# STM32MP21_CA35 register map
File version: 0.4
CPU: CM33 r0p1, little endian, MPU, FPU, vendor SysTick, 8 interrupt priority bits
Registers are 32-bit, read-write, reset 0x0 unless marked. A register's access mark holds for its fields unless they carry their own. Offsets are from the block's base; [hi:lo] are bit positions; {n}, {i} and the like mark numbered series; 'fields as' and 'values as' point back to an identical list.

## MDF1 — MDF register block
Base 0x404D0000
Same registers: MDF1_S 0x504D0000
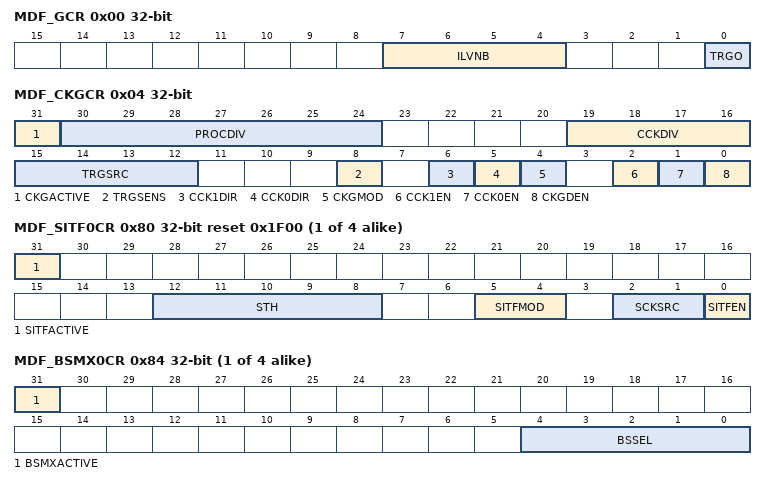
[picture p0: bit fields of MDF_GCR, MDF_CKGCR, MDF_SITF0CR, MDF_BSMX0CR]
0x00 MDF_GCR — MDF global control register
  [7:4] ILVNB — Interleaved number This bit field is set and reset by software. it enables or disables the interleaved-transfer mode and defines how many digital filters work in this mode. This bit field cannot be changed when DFLTEN = 1 in MDF_DFLT0CR. ... Note: This bit field can be write-protected (refer to Section 44.4.15 for details).
    0=Interleaved-transfer mode disabled; 1=Data from DFLT0 and DFLT1 are interleaved; 2=Data from DFLT0, DFLT1 and DFLT2 are interleaved; 15=Data from DFLT0 to DFLT15 are interleaved
  [0] TRGO — Trigger output control This bit is set by software and reset by hardware. It is used to start the acquisition of several filters synchronously. It is also able to synchronize several MDF together by controlling the mdf_trgo signal.
    0=Write 0 has no effect. Read 0 means that the trigger can be set again to 1.; 1=Write 1 generates a positive pulse on mdf_trgo signal and triggers the acquisition on the enabled filters having ACQMOD[2:0] = 0x1 and selecting TRGO as trigger. Read 1 means that the trigger pulse is still active.
0x04 MDF_CKGCR — MDF clock generator control register
  [31] CKGACTIVE ro — Clock generator active flag This bit is set and cleared by hardware. This flag must be used by the application to check if the clock generator is effectively enabled (active) or not. The protected fields of this function can only be updated when CKGACTIVE = 0 (refer to Section 44.4.15 for details). The delay between a transition on CKGDEN and a transition on CKGACTIVE is two periods of AHB clock and two periods of mdf_proc_ck.
    0=The clock generator is not active and can be configured if needed; 1=The clock generator is active and protected fields cannot be configured
  [30:24] PROCDIV — Divider to control the serial interface clock This bit field is set and reset by software. It is used to adjust the frequency of the clock provided to the SITF. This bit field must not be changed if one of the filters is enabled (DFTEN = 1). ... Note: This bit field can be write-protected (refer to Section 44.4.15 for details).
    0=mdf_ker_ck provided to the SITF; 1=mdf_ker_ck/2 provided to the SITF
  [19:16] CCKDIV — Divider to control the MDF_CCK clock This bit field is set and reset by software. It is used to adjust the frequency of the MDF_CCK clock. The input clock of this divider is the clock provided to the SITF. More globally, the frequency of the MDF_CCK is given by the following formula: This bit field must not be changed if one of the filters is enabled (DFTEN = 1). ... Note: This bit field can be write-protected (refer to Section 44.4.15 for details).
    0=The MDF_CCK clock is mdf_proc_ck; 1=The MDF_CCK clock is mdf_proc_ck / 2; 2=The MDF_CCK clock is mdf_proc_ck / 3; 15=The MDF_CCK clock is mdf_proc_ck / 16
  [15:12] TRGSRC — Digital filter trigger signal selection This bit field is set and cleared by software.It is used to select which external signals trigger for the corresponding filter. This bit field is not significant if CKGMOD = 0. 000x: TRGO selected ... Note: This bit field can be write-protected (refer to Section 44.4.15 for details.)
    2=mdf_trg[0] selected; 3=mdf_trg[1] selected; 15=mdf_trg[13] selected
  [8] TRGSENS — CKGEN trigger sensitivity selection This bit is set and cleared by software. It is used to select the trigger sensitivity of the trigger signals. This bit is not significant if the CKGMOD = 0. Note: When the trigger source is TRGO, TRGSENS value is not taken into account. When TRGO is selected, the sensitivity is forced to falling edge. This bit can be write-protected (refer to Section 44.4.15 for details).
    0=A rising edge event triggers the activation of CKGEN dividers; 1=A falling edge even triggers the activation of CKGEN dividers
  [6] CCK1DIR — MDF_CCK1 direction This bit is set and reset by software.It is used to control the direction of the MDF_CCK1 pin. Note: This bit can be write-protected (refer to Section 44.4.15 for details).
    0=MDF_CCK1 pin direction is in input; 1=MDF_CCK1 pin direction is in output
  [5] CCK0DIR — MDF_CCK0 direction This bit is set and reset by software.It is used to control the direction of the MDF_CCK0. Note: This bit can be write-protected (refer to Section 44.4.15 for details).
    0=MDF_CCK0 pin direction is in input; 1=MDF_CCK0 pin direction is in output
  [4] CKGMOD — Clock generator mode This bit is set and reset by software. It is used to define the way the clock generator is enabled. This bit must not be changed if one of the filters is enabled (DFTEN = 1). Note: This bit can be write-protected (refer to Section 44.4.15 for details).
    0=The kernel clock is provided to the dividers as soon as CKGDEN is set to 1; 1=The kernel clock is provided to the dividers when CKGDEN is set to 1 and the trigger condition met
  [2] CCK1EN — MDF_CCK1 clock enable This bit is set and reset by software. It is used to control the generation of the bitstream clock on the MDF_CCK1 pin.
    0=Bitstream clock not generated; 1=Bitstream clock generated on the MDF_CCK1 pad
  [1] CCK0EN — MDF_CCK0 clock enable This bit is set and reset by software.It is used to control the generation of the bitstream clock on the MDF_CCK0 pin.
    0=Bitstream clock not generated; 1=Bitstream clock generated on the MDF_CCK0 pad
  [0] CKGDEN — CKGEN dividers enable This bit is set and reset by software. It is used to enable/disable the clock dividers of the CKGEN: PROCDIV and CCKDIV.
    0=CKGEN dividers disabled; 1=CKGEN dividers enabled
{0x80+0x80*i} MDF_SITF{i}CR reset 0x1F00 (i=0..3) — MDF serial interface control register {i}
  [31] SITFACTIVE ro — Serial interface active flag This bit is set and cleared by hardware. It is used by the application to check if the serial interface is effectively enabled (active) or not. The protected fields of this function can only be updated when the SITFACTIVE is set to 0 (refer to Section 44.4.15 for details). The delay between a transition on SITFEN and a transition on SITFACTIVE is two periods of AHB clock and two periods of mdf_proc_ck.
    0=The serial interface is not active and can be configured if needed; 1=The serial interface is active and protected fields cannot be configured
  [12:8] STH — Manchester symbol threshold/SPI threshold This bit field is set and cleared by software. It is used for Manchester mode to define the expected symbol threshold levels (refer to Manchester mode for details on computation). In addition this bit field is used to define the timeout value for the clock absence detection in Normal SPI mode. STH[4:0] values lower than four are invalid. Note: This bit field can be write-protected (refer to Section 44.4.15 for details).
  [5:4] SITFMOD — Serial interface type This bit field is set and cleared by software. it is used to define the serial interface type. Note: This bit field can be write-protected (refer to Section 44.4.15 for details).
    0=LF_MASTER SPI mode; 1=Normal SPI mode; 2=Manchester mode: rising edge = logic 0, falling edge = logic 1; 3=Manchester mode: rising edge = logic 1, falling edge = logic 0
  [2:1] SCKSRC — Serial clock source This bit field is set and cleared by software. it is used to select the clock source of the serial interface. 1x: Serial clock source is MDF_CKIx (not allowed in LF_MASTER SPI mode). Note: This bit field can be write-protected (refer to Section 44.4.15 for details).
    0=Serial clock source is MDF_CCK0; 1=Serial clock source is MDF_CCK1
  [0] SITFEN — Serial interface enable This bit is et and cleared by software. It is used to enable/disable the serial interface.
    0=Serial interface disabled; 1=Serial interface enabled
{0x84+0x80*i} MDF_BSMX{i}CR (i=0..3) — MDF bitstream matrix control register {i}
  [31] BSMXACTIVE ro — BSMX active flag This bit is set and cleared by hardware. It is used by the application to check if the BSMX is effectively enabled (active) or not. BSSEL[4:0] can only be updated when the BSMXACTIVE is set to 0. Th is BSMXACTIVE flag is a logical OR between OLDACTIVE, DFLTACTIVE, and SCDACTIVE flags. Both of them must be set to 0 in order update BSSEL[4:0] bit field.
    0=BSMX is not active and can be configured if needed; 1=BSMX is active and protected fields cannot be configured
  [4:0] BSSEL — Bitstream Selection This bit field is set and cleared by software. It is used to select the bitstream to be processed for DFLTx and SCDx. The size of this bit field depends on the number of DFLTx instantiated. If this bit field selects a not instantiated input, the MDF selects the valid stream bsx_f having the higher index number. ... Note: This bit field can be write-protected (refer to Section 44.4.15 for details).
    0=bs0_r provided to DFLTx and SCDx; 1=bs0_f provided to DFLTx and SCDx; 2=bs1_r provided to DFLTx and SCDx (if instantiated); 3=bs1_f provided to DFLTx and SCDx (if instantiated); 30=bs15_r provided to DFLTx and SCDx (if instantiated); 31=bs15_f provided to DFLTx and SCDx (if instantiated)
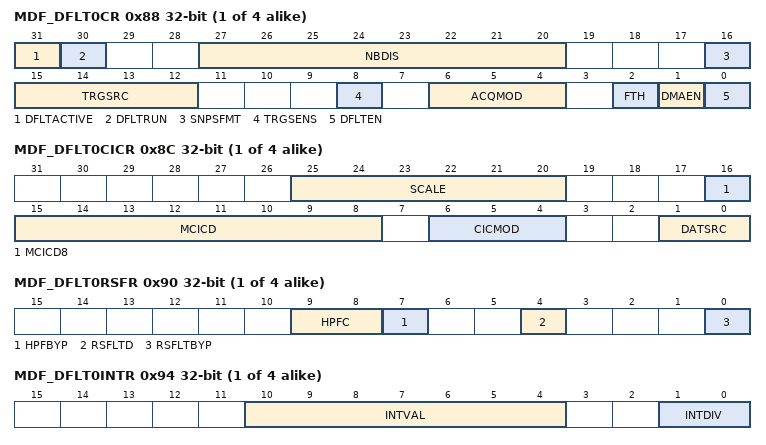
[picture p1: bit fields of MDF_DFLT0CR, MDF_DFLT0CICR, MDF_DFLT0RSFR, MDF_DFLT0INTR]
{0x88+0x80*i} MDF_DFLT{i}CR (i=0..3) — MDF digital filter control register {i}
  [31] DFLTACTIVE ro — Digital filter active flag This bit is set and cleared by hardware. It indicates if the digital filter is active: can be running or waiting for events.
    0=Digital filter not active (can be re-enabled again, via DFLTEN, if needed); 1=Digital filter active
  [30] DFLTRUN ro — Digital filter run status flag This bit is set and cleared by hardware. It indicates if the digital filter is running or not.
    0=Digital filter not running and ready to accept a new trigger event; 1=Digital filter running
  [27:20] NBDIS — Number of samples to be discarded This bit field is set and cleared by software. it is used to define the number of samples to be discarded every time the DFLTx is re-started. ... Note: This bit field can be write-protected (refer to Section 44.4.15 for details).
    0=No sample discarded; 1=1 sample discarded
  [16] SNPSFMT — Snapshot data format This bit is set and cleared by software. It is used to select the data format for the snapshot mode. Note: This bit can be write-protected (refer to Section 44.4.15 for details).
    0=Integrator counter (INT_CNT) not inserted into MDF_SNPSxDR, leaving a data resolution of 23 bits; 1=Integrator counter (INT_CNT) inserted at position [15:9] of MDF_SNPSxDR, leaving a data resolution of 16 bits
  [15:12] TRGSRC — Digital filter trigger signal selection This bit field is set and cleared by software. It is used to select which external signals trigger the corresponding filter. ... Note: This bit field can be write-protected (refer to Section 44.4.15 for details).
    0=TRGO selected; 1=OLDx event selected; 2=mdf_trg[0] selected; 15=mdf_trg[13] selected
  [8] TRGSENS — Digital filter trigger sensitivity selection this bit is set and cleared by software. It is used to select the trigger sensitivity of the external signals When the trigger source is TRGO or OLDx event, TRGSENS value is not taken into account. When TRGO is selected, the sensitivity is forced to falling edge, when OLDx event is selected, the sensitivity is forced to rising edge. Note: This bit can be write-protected (refer to Section 44.4.15 for details).
    0=A rising edge event triggers the acquisition; 1=A falling edge even triggers the acquisition
  [6:4] ACQMOD — Digital filter trigger mode This bit field is set and cleared by software. It is used to select the filter trigger mode. Others: same a 000 Note: This bit field can be write-protected (refer to Section 44.4.15 for details).
    0=Asynchronous continuous acquisition mode; 1=Asynchronous single-shot acquisition mode; 2=Synchronous continuous acquisition mode; 3=Synchronous, single-shot acquisition mode; 4=Window continuous acquisition mode; 5=Synchronous snapshot mode
  [2] FTH — RXFIFO threshold selection This bit is set and cleared by software. It is used to select the RXFIFO threshold. This bit is not significant for RXFIFOs working in interleaved-transfer mode (see Interleaved-transfer mode for details). Note: This bit can be write-protected (refer to Section 44.4.15 for details).
    0=RXFIFO threshold event generated when the RXFIFO is not empty; 1=RXFIFO threshold event generated when the RXFIFO is half-full
  [1] DMAEN — DMA requests enable This bit is set and cleared by software. It is used to control the generation of DMA request to transfer the processed samples into the memory. Note: This bit can be write-protected (refer to Section 44.4.15 for details).
    0=DMA interface for the corresponding digital filter disabled; 1=DMA interface for the corresponding digital filter enabled
  [0] DFLTEN wo — Digital filter enable This bit is set and cleared by software. It is used to control the start of acquisition of the corresponding digital filter path. This bit behavior depends on ACQMOD[2:0]and external events. The serial or parallel interface delivering the samples must be enabled as well.
    0=Acquisition immediately stopped; 1=Acquisition immediately started if ACQMOD[2:0] = 00x or 101, or acquisition started when the proper trigger event occurs if ACQMOD[2:0] = 01x or 100
{0x8C+0x80*i} MDF_DFLT{i}CICR (i=0..3) — MDF digital filter configuration register {i}
  [25:20] SCALE — Scaling factor selection This bit field is set and cleared by software. It is used to select the gain to be applied at CIC output (refer to Table 403 for details). If the application attempts to write a new gain value while the previous one is not yet applied, this new gain value is ignored. Reading back this bit field informs the application on the current gain value. ... ... Others: Reserved
    0=0 dB; 1=+ 3.5 dB; 2=+ 6 dB or shift left by 1 bit; 24=+ 72 dB or shift left by 12 bits; 32=- 48.2 dB or shift right by 8 bits (default value); 33=- 44.6 dB; 34=- 42.1 dB or shift right by 7 bits; 35=- 38.6 dB; 46=- 6 dB or shift right by 1 bit; 47=- 2.5 dB
  [16] MCICD8 — CIC decimation ratio selection This bit field is set and cleared by software. It is used to select the CIC decimation ratio. A decimation ratio smaller than two is not allowed. The decimation ratio is given by (CICDEC+1). ... Note: This bit field can be write-protected (refer to Section 44.4.15 for details).
    0=Decimation ratio is 2; 1=Decimation ratio is 2
  [15:8] MCICD — CIC decimation ratio selection This bit field is set and cleared by software. It is used to select the CIC decimation ratio. A decimation ratio smaller than two is not allowed. The decimation ratio is given by (CICDEC+1). ... Note: This bit field can be write-protected (refer to Section 44.4.15 for details).
    0=Decimation ratio is 2; 1=Decimation ratio is 2
  [6:4] CICMOD — Select the CIC mode This bit field is set and cleared by software.It is used to select the configuration and the order of the MCIC. When CICMOD[2:0] = 0xx, the CIC is split into two filters: the main CIC (MCIC) and the auxiliary CIC (ACIC, used for the out-off limit detector). others: CIC configured in single Sincsupsuperior5/supsuperior filter Note: This bit field can be write-protected (refer to Section 44.4.15 for details).
    0=CIC split in two filters and MCIC configured in FastSinc filter; 1=CIC split in two filters and MCIC configured in Sincsupsuperior1/supsuperior filter; 2=CIC split in two filters and MCIC configured in Sincsupsuperior2/supsuperior filter; 3=CIC split in two filters and MCIC configured in Sincsupsuperior3/supsuperior filter; 4=CIC configured in single Sincsupsuperior4/supsuperior filter
  [1:0] DATSRC — Source data for the digital filter This bit field is set and cleared by software. 0x: Stream coming from the BSMX selected Note: This bit field can be write-protected (refer to Section 44.4.15 for details).
    2=Stream coming from the ADCITF1 selected; 3=Stream coming from the ADCITF2 selected
{0x90+0x80*i} MDF_DFLT{i}RSFR (i=0..3) — MDF reshape filter configuration register {i}
  [9:8] HPFC — High-pass filter cut-off frequency This bit field is set and cleared by software. It is used to select the cut-off frequency of the high-pass filter. FsubsuperiorPCM/subsuperior represents the sampling frequency at HPF input. Note: This bit field can be write-protected (refer to Section 44.4.15 for details).
    0=Cut-off frequency = 0.000625 x FsubsuperiorPCM/subsuperior; 1=Cut-off frequency = 0.00125 x FsubsuperiorPCM/subsuperior; 2=Cut-off frequency = 0.00250 x FsubsuperiorPCM/subsuperior; 3=Cut-off frequency = 0.00950 x FsubsuperiorPCM/subsuperior
  [7] HPFBYP — High-pass filter bypass This bit is set and cleared by software. It is used to bypass the high-pass filter. Note: This bit can be write-protected (refer to Section 44.4.15 for details).
    0=HPF not bypassed (default value); 1=HPF bypassed
  [4] RSFLTD — Reshaper filter decimation ratio This bit is set and cleared by software. It is used to select the decimation ratio for the reshape filter. Note: This bit can be write-protected (refer to Section 44.4.15 for details).
    0=Decimation ratio is 4 (default value); 1=Decimation ratio is 1
  [0] RSFLTBYP — Reshaper filter bypass This bit is set and cleared by software. It is used to bypass the reshape filter and its decimation block. Note: This bit can be write-protected (refer to Section 44.4.15 for details).
    0=Reshape filter not bypassed (default value); 1=Reshape filter bypassed
{0x94+0x80*i} MDF_DFLT{i}INTR (i=0..3) — MDF integrator configuration register {i}
  [10:4] INTVAL — Integration value selection This bit field is set and cleared by software. It is used to select the integration value. ... Note: This bit field can be write-protected (refer to Section 44.4.15 for details).
    0=The integration value is 1, meaning bypass mode (default after reset); 1=The integration value is 2
  [1:0] INTDIV — Integrator output division This bit field is set and cleared by software. It is used to rescale the signal at the integrator output in order keep the data width lower than 24 bits. Note: This bit field can be write-protected (refer to Section 44.4.15 for details).
    0=The integrator data outputs are divided by 128 (default value); 1=The integrator data outputs are divided by 32; 2=The integrator data outputs are divided by 4; 3=The integrator data outputs are not divided
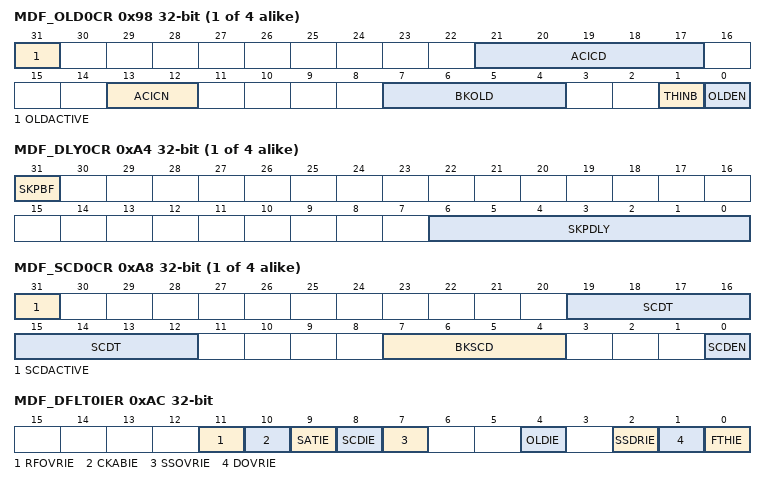
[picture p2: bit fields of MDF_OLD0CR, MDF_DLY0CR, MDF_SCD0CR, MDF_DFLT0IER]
{0x98+0x80*i} MDF_OLD{i}CR (i=0..3) — MDF out-of limit detector control register {i}
  [31] OLDACTIVE ro — OLDx active flag This bit is set and cleared by hardware. It is used to check if the OLDx is effectively enabled (active) or not. The protected fields and registers of this function can only be updated when the OLDACTIVE is set to 0 (refer to Section 44.4.15 for details). The delay between a transition on OLDEN and a transition on OLDACTIVE is two periods of AHB clock and two periods of mdf_proc_ck.
    0=OLDx not active and can be configured if needed; 1=OLDx active and protected fields cannot be configured
  [21:17] ACICD — OLDx CIC decimation ratio selection This bit field is set and cleared by software. It is used to select the decimation ratio of the ACIC. It is only taken into account by the MDF when CICMOD[2:0] = 0xx. The decimation ratio is given by (ACICD + 1). ... Note: This bit field can be write-protected (refer to Section 44.4.15 for details).
    0=Decimation ratio is 1; 1=Decimation ratio is 2
  [13:12] ACICN — OLDx CIC order selection This bit field is set and cleared by software. It is used to select the ACIC type and order. It is only taken into account by the MDF when CICMOD[2:0] = 0xx. Note: This bit field can be write-protected (refer to Section 44.4.15 for details).
    0=FastSinc filter type; 1=Sincsupsuperior1/supsuperior filter type; 2=Sincsupsuperior2/supsuperior filter type; 3=Sincsupsuperior3/supsuperior filter type
  [7:4] BKOLD — Break signal assignment for out-of limit detector This bit field is set and cleared by software. BKOLD[i] = 0: Break signal (mdf_break[i]) not assigned to threshold event BKOLD[i] = 1: Break signal (mdf_break[i]) assigned to threshold event Note: This bit field can be write-protected (refer to Section 44.4.15 for details).
  [1] THINB — Threshold In band This bit is set and cleared by software. Note: This bit can be write-protected (refer to Section 44.4.15 for details).
    0=The OLDx generates an event if the signal is lower than OLDTHL or higher than OLDTHH (default value); 1=The OLDx generates an event if the signal is lower than OLDTHH and higher than OLDTHL
  [0] OLDEN — OLDx enable This bit is set and cleared by software.
    0=OLDx disabled (default value); 1=OLDx enabled, including the ACIC filter working in continuous mode
{0x9C+0x80*i} MDF_OLD{i}THLR (i=0..3) — MDF OLD{i} low threshold register {i}
  [25:0] OLDTHL — OLD low threshold value This bit field is set and cleared by software. OLDTHL represents a 26-bit signed value. The real threshold compared to the signal provided by the filter is OLDTHL. Note: This bit field can be write-protected (refer to Section 44.4.15 for details).
{0xA0+0x80*i} MDF_OLD{i}THHR (i=0..3) — MDF OLD{i} high threshold register {i}
  [25:0] OLDTHH — OLDx high threshold value This bit field is set and cleared by software. OLDTHH represents a 26-bit signed value. The real threshold compared to the signal provided by the filter is OLDTHH. Note: This bit field can be write-protected (refer to Section 44.4.15 for details).
{0xA4+0x80*i} MDF_DLY{i}CR (i=0..3) — MDF delay control register {i}
  [31] SKPBF ro — Skip busy flag This bit is set and cleared by hardware. It is used to control if the delay sequence is completed.
    0=MDF ready to accept a new value into SKPDLY[6:0]; 1=Last valid SKPDLY[6:0] still under processing
  [6:0] SKPDLY — Delay to apply to a bitstream This bit field is set and cleared by software. It defines the number of input samples that are skipped. Skipping is applied immediately after writing to this bit field, if SKPBF = 0 and the corresponding DFLTEN = 1. If SKPBF = 1, the value written into the register is ignored by the delay state machine. ...
    0=No input sample skipped; 1=1 input sample skipped
{0xA8+0x80*i} MDF_SCD{i}CR (i=0..3) — MDF short circuit detector control register {i}
  [31] SCDACTIVE ro — SCDx active flag This bit is set and cleared by hardware. It is used to check if the SCDx is effectively enabled (active) or not. The protected fields of this function can only be updated when the SCDACTIVE is set to 0 (refer to Section 44.4.15 for details). The delay between a transition on SCDEN and a transition on SCDACTIVE is two periods of AHB clock and two periods of mdf_proc_ck.
    0=SCDx not active and can be configured if needed; 1=SCDx active and protected fields cannot be configured
  [19:12] SCDT — SCDx threshold This bit field is set and cleared by software. These bits are written by software to define the threshold counter for SCDx. If this value is reached, a short-circuit detector event occurs on a given input stream. ... Note: This bit field can be write-protected (refer to Section 44.4.15 for details).
    0=2 consecutive 1's or 0's generate an event; 1=2 consecutive 1's or 0's generate an event
  [7:4] BKSCD — Break signal assignment for short circuit detector This bit field is set and cleared by software. BKSCD[i] = 0: Break signal (mdf_break[i]) not assigned to this SCD event BKSCD[i] = 1: Break signal (mdf_break[i]) assigned to this SCD event Note: This bit field can be write-protected (refer to Section 44.4.15 for details).
  [0] SCDEN — SCDx enable This bit is set and cleared by software.
    0=SCDx disabled; 1=SCDx enabled,
0xAC MDF_DFLT0IER — MDF DFLT0 interrupt enable register 0
  [11] RFOVRIE — Reshape filter overrun interrupt enable This bit is set and cleared by software.
    0=Reshape filter overrun interrupt disabled; 1=Reshape filter overrun interrupt enabled
  [10] CKABIE — Clock absence detection interrupt enable This bit is set and cleared by software.
    0=Clock absence interrupt disabled; 1=Clock absence interrupt enabled
  [9] SATIE — Saturation detection interrupt enable This bit is set and cleared by software.
    0=Saturation interrupt disabled; 1=Saturation interrupt enabled
  [8] SCDIE — SCD0 interrupt enable This bit is set and cleared by software.
    0=SCD0 interrupt disabled; 1=SCD0 interrupt enabled
  [7] SSOVRIE — Snapshot overrun interrupt enable This bit is set and cleared by software.
    0=Snapshot overrun interrupt disabled; 1=Snapshot overrun interrupt enabled
  [4] OLDIE — OLD0 interrupt enable This bit is set and cleared by software.
    0=OLD0 event interrupt disabled; 1=OLD0 event interrupt enabled
  [2] SSDRIE — Snapshot data ready interrupt enable This bit is set and cleared by software.
    0=Snapshot data ready interrupt disabled; 1=Snapshot data ready interrupt enabled
  [1] DOVRIE — Data overflow interrupt enable This bit is set and cleared by software.
    0=Data overflow interrupt disabled; 1=Data overflow interrupt enabled
  [0] FTHIE — RXFIFO threshold interrupt enable This bit is set and cleared by software.
    0=RXFIFO threshold interrupt disabled; 1=RXFIFO threshold interrupt enabled
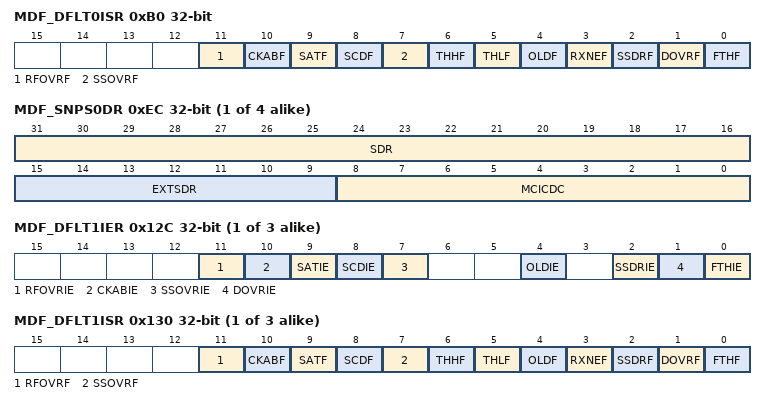
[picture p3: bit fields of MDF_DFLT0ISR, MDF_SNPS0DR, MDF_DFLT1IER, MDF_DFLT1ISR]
0xB0 MDF_DFLT0ISR — MDF DFLT0 interrupt status register 0
  [11] RFOVRF — Reshape filter overrun detection flag This bit is set by hardware and cleared by software by writing this bit to 1.
    0=Read 0 means that no reshape filter overrun is detected. Write 0 has no effect.; 1=Read 1 means that reshape filter overrun is detected. Write 1 clears this flag.
  [10] CKABF — Clock absence detection flag This bit is set by hardware and cleared by software by writing this bit to 1.
    0=Read 0 means that no clock absence is detected. Write 0 has no effect.; 1=Read 1 means that a clock absence is detected. Write 1 clears this flag.
  [9] SATF — Saturation detection flag This bit is set by hardware and cleared by software by writing this bit to 1.
    0=Read 0 means that no saturation is detected. Write 0 has no effect.; 1=Read 1 means that a saturation is detected. Write 1 clears this flag.
  [8] SCDF — Short-circuit detector flag This bit is set by hardware and cleared by software by writing this bit to 1.
    0=Read 0 means that no SCD0 event is detected. Write 0 has no effect.; 1=Read 1 means that a SCD0 event is detected. Write 1 clears this flag.
  [7] SSOVRF — Snapshot overrun flag This bit is set by hardware and cleared by software by writing this bit to 1.
    0=Read 0 means that no snapshot overrun event is detected. Write 0 has no effect.; 1=Read 1 means that a snapshot overrun event is detected. Write 1 clears this flag.
  [6] THHF ro — High-threshold status flag This bit is set by hardware and cleared by software by writing this bit to 1. It indicates the status of the high-threshold comparator when the last OLD0 event occurred. This bit gives additional information on the conditions triggering the last OLD0 event. It can be cleared by writing OLDF flag to 1.
    0=The signal was lower than OLDTHH when the last OLD0 event occurred; 1=The signal was higher than OLDTHH when the last OLD0 event occurred
  [5] THLF ro — Low-threshold status flag This bit is set by hardware and cleared by software by writing this bit to 1. It indicates the status of the low-threshold comparator when the last OLD0 event occurred. This bit gives additional information on the conditions triggering the last OLD0 event. It can be cleared by writing OLDF flag to 1.
    0=The signal was higher than OLDTHL when the last OLD0 event occurred; 1=The signal was lower than OLDTHL when the last OLD0 event occurred
  [4] OLDF — OLD0 flag This bit is set by hardware and cleared by software by writing this bit to 1.
    0=Read 0 means that no OLD0 event is detected. Write 0 has no effect.; 1=Read 1 means that an OLD0 event is detected Write 1 clears THHF, THLF and OLDF
  [3] RXNEF ro — RXFIFO not-empty flag this bit is set and cleared by hardware according to the RXFIFO level.
    0=RXFIFO empty; 1=RXFIFO not empty
  [2] SSDRF — Snapshot data ready flag This bit is set by hardware and cleared by software by writing this bit to 1.
    0=Read 0 means that no data is available. Write 0 has no effect.; 1=Read 1 means that a new data is available. Write 1 clears this flag.
  [1] DOVRF — Data overflow flag This bit is set by hardware and cleared by software by writing this bit to 1.
    0=Read 0 means that no overflow is detected. Write 0 has no effect.; 1=Read 1 means that an overflow is detected; Write 1 clears this flag
  [0] FTHF ro — RXFIFO threshold flag This bit is set by hardware and cleared by hardware when the RXFIFO level is lower than the threshold.
    0=RXFIFO threshold not reached; 1=RXFIFO threshold reached
{0xB4+0x80*i} MDF_OEC{i}CR (i=0..3) — MDF offset error compensation control register {i}
  [25:0] OFFSET — Offset error compensation This bit field is set and cleared by software. If the application attempts to write a new offset value while the previous one is not yet applied, this new offset value is ignored. Reading back this bit field informs the application on the current offset value. This bit field represents the value to be subtracted to the signal before going to the SCALE.
{0xEC+0x80*i} MDF_SNPS{i}DR ro (i=0..3) — MDF snapshot data register {i}
  [31:16] SDR — Contains the 16 MSB of the last valid data processed by the digital filter.
  [15:9] EXTSDR — Extended data size If SNPSFMT = 0, this bit field contains the bits 7 to 1 of the last valid data processed by the digital filter. If SNPSFMT = 1, this bit field contains the INT accumulator counter value when the last trigger event occurs (INT_CNT).
  [8:0] MCICDC — Contains the MCIC decimation counter value when the last trigger event occurs (MCIC_CNT)
{0xF0+0x80*i} MDF_DFLT{i}DR ro (i=0..3) — MDF digital filter data register {i}
  [31:8] DR — Data processed by digital filter
{0xAC+0x80*i} MDF_DFLT{i}IER (i=1..3) — MDF DFLT{i} interrupt enable register {i}
  [11] RFOVRIE — Reshape filter overrun interrupt enable This bit is set and cleared by software.
    values as MDF_DFLT0IER.RFOVRIE
  [10] CKABIE — Clock absence detection interrupt enable This bit is set and cleared by software.
    values as MDF_DFLT0IER.CKABIE
  [9] SATIE — Saturation detection interrupt enable This bit is set and cleared by software.
    values as MDF_DFLT0IER.SATIE
  [8] SCDIE — SCDx interrupt enable This bit is set and cleared by software.
    0=SCDx interrupt disabled; 1=SCDx interrupt enabled
  [7] SSOVRIE — Snapshot overrun interrupt enable This bit is set and cleared by software.
    values as MDF_DFLT0IER.SSOVRIE
  [4] OLDIE — OLDx interrupt enable This bit is set and cleared by software.
    0=OLDx event interrupt disabled; 1=OLDx event interrupt enabled
  [2] SSDRIE — Snapshot data ready interrupt enable This bit is set and cleared by software.
    values as MDF_DFLT0IER.SSDRIE
  [1] DOVRIE — Data overflow interrupt enable This bit is set and cleared by software.
    values as MDF_DFLT0IER.DOVRIE
  [0] FTHIE — RXFIFO threshold interrupt enable This bit is set and cleared by software.
    values as MDF_DFLT0IER.FTHIE
{0xB0+0x80*i} MDF_DFLT{i}ISR (i=1..3) — MDF DFLT{i} interrupt status register {i}
  [11] RFOVRF — Reshape filter overrun detection flag This bit is set by hardware and cleared by software by writing this bit to 1.
    values as MDF_DFLT0ISR.RFOVRF
  [10] CKABF — Clock absence detection flag This bit is set by hardware and cleared by software by writing this bit to 1.
    values as MDF_DFLT0ISR.CKABF
  [9] SATF — Saturation detection flag This bit is set by hardware and cleared by software by writing this bit to 1.
    values as MDF_DFLT0ISR.SATF
  [8] SCDF — Short-circuit detector flag This bit is set by hardware and cleared by software by writing this bit to 1.
    0=Read 0 means that no SCD event is detected. Write 0 has no effect.; 1=Read 1 means that a SCD event is detected. Write 1 clears this flag.
  [7] SSOVRF — Snapshot overrun flag This bit is set by hardware and cleared by software by writing this bit to 1.
    values as MDF_DFLT0ISR.SSOVRF
  [6] THHF ro — High-threshold status flag This bit is set by hardware and cleared by software by writing this bit to 1. It indicates the status of the high-threshold comparator when the last OLDx event occurred. This bit gives additional information on the conditions triggering the last OLDx event. It can be cleared by writing OLDF flag to 1.
    0=The signal was lower than OLDTHH when the last OLDx event occurred; 1=The signal was higher than OLDTHH when the last OLDx event occurred
  [5] THLF ro — Low-threshold status flag This bit is set by hardware and cleared by software by writing this bit to 1. It indicates the status of the low-threshold comparator when the last OLDx event occurred. This bit gives additional information on the conditions triggering the last OLDx event. It can be cleared by writing OLDF flag to 1.
    0=The signal was higher than OLDTHL when the last OLDx event occurred; 1=The signal was lower than OLDTHL when the last OLDx event occurred
  [4] OLDF — OLDx flag This bit is set by hardware and cleared by software by writing this bit to 1.
    0=Read 0 means that no OLDx event is detected. Write 0 has no effect.; 1=Read 1 means that an OLDx event is detected Write 1 clears THHF, THLF and OLDF
  [3] RXNEF ro — RXFIFO not-empty flag this bit is set and cleared by hardware according to the RXFIFO level.
    0=RXFIFO empty; 1=RXFIFO not empty
  [2] SSDRF — Snapshot data ready flag This bit is set by hardware and cleared by software by writing this bit to 1.
    values as MDF_DFLT0ISR.SSDRF
  [1] DOVRF — Data overflow flag This bit is set by hardware and cleared by software by writing this bit to 1.
    values as MDF_DFLT0ISR.DOVRF
  [0] FTHF ro — RXFIFO threshold flag This bit is set by hardware and cleared by hardware when the RXFIFO level is lower than the threshold.
    0=RXFIFO threshold not reached; 1=RXFIFO threshold reached
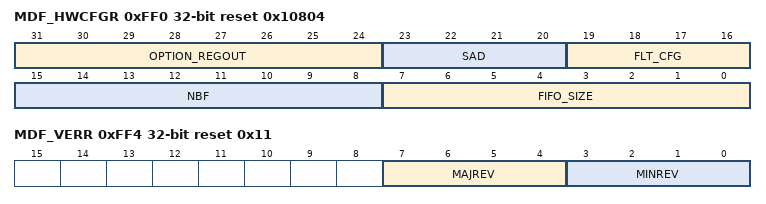
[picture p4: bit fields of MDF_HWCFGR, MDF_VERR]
0xFF0 MDF_HWCFGR ro reset 0x10804 — MDF hardware configuration register
  [31:24] OPTION_REGOUT — Support of MDF_OR register ... Others: Invalid values
    0=MDF_OR not implemented; 1=MDF_OR implemented with only one control bit at position 0
  [23:20] SAD — Sound activity detection
    0=SAD not implemented; 1=SAD implemented
  [19:16] FLT_CFG — Digital filter configuration
    0=Reduced set of features to mainly address audio use-cases; 1=Full set of features, with associated blocks for motor control applications
  [15:8] NBF — Number of digital filter paths and serial interfaces ... ...
    1=1 digital filter instance implemented; 2=2 digital filter instances implemented; 6=6 digital filter instances implemented; 16=16 digital filter instances implemented
  [7:0] FIFO_SIZE — FIFO size for MDF Others: Invalid values
0xFF4 MDF_VERR ro reset 0x11 — MDF version register
  [7:4] MAJREV — MDF major revision
  [3:0] MINREV — MDF minor revision
0xFF8 MDF_IPIDR ro reset 0x110032 — MDF identification register
  [31:0] ID — MDF identifier value
0xFFC MDF_SIDR ro — MDF size identification register
  [31:0] SID — Size identification These bits returns the size of the memory region allocated to the MDF registers. The size of this memory region is of 4 Kbytes.
